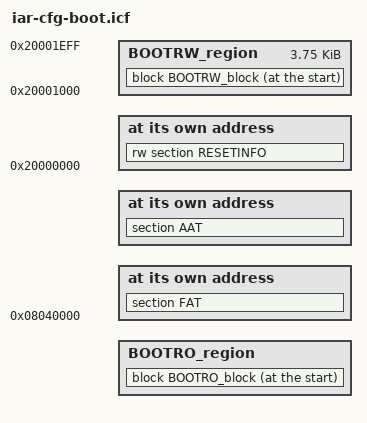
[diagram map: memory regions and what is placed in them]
// IAR V5 ILINK linker configuration file for bootloaders.
//
// Copyright 2009 by Ember Corporation. All rights reserved.                *80*

define memory mem with size = 4G;

// Lowest-common-denominator definitions that will work with all chip variations
//   RAM_TOP is artificially decreased to avoid interference with debug channels
define symbol RAM_BOTTOM          = 0x20000000;
define symbol RAM_TOP             = 0x20001EFF;

define symbol MFB_BOTTOM          = 0x08000000;
define symbol MFB_TOP             = 0x0801FFFF;

define symbol FIB_BOTTOM          = 0x08040000;
define symbol FIB_TOP             = 0x080407FF;

//=============================================================================
// Flash placement.

// Note: The bootloader does not support interrupts, so it does not include any
// interrupt vector table definitions other than what is included in the BAT.

// Define a region and block for containing the bootloader RO sections
// The Bootloader image lives at the bottom of the flash.  The BTL_SIZE 
// definition is passed in from the project definitions.
define symbol BOOTRO_BOTTOM          = MFB_BOTTOM;
define symbol BOOTRO_TOP             = MFB_BOTTOM + (BTL_SIZE-1);
define region BOOTRO_region          = mem:[from BOOTRO_BOTTOM to BOOTRO_TOP];
define block BOOTRO_block with fixed order { ro section BAT, 
                                             ro section .text, 
                                             ro section .rodata, 
                                             ro section .data_init };
"APP ro": place at start of BOOTRO_region { block BOOTRO_block };

// The FAT lives at a fixed address within the FIB
"FAT": place at address mem:FIB_BOTTOM { section FAT };

// The AAT will live immediately after the end of the bootloader
define symbol AAT_BOTTOM              = BOOTRO_TOP + 1;
"AAT": place at address mem:AAT_BOTTOM { section AAT };

//=============================================================================
// RAM placement.

// The call stack and reset info sections normally overlay on top of each other
//  at the bottom of ram, but since application bootloaders need space to load 
//  in a recovery image RAMEXE at the bottom of RAM, we only place the overlaid 
//  reset info section at the bottom of ram, and move the rest of the 
//  bootloaders ram usage up by 4K so that it doesn't get overwritten when
//  loading the RAMEXE.  The reset info area must live at the base of RAM as it
//  occupies this fixed location across all bootloader, application, and ramexe
//  images.
"RESETINFO": place at address mem:RAM_BOTTOM { rw section RESETINFO };

//Do not include the intializer tables or IAR init library code for any RW.
do not initialize { rw };
//But, .data and .textrw will be manually initialized so include init tables
// for them.
initialize manually { section .data, section .textrw };

// Define a region and block for containing the bootloader RW sections
//  Leave 4k free at the bottom of RAM to allow for recovery image
//  RAMEXE executable to be imported from eeprom by application bootloaders
define symbol BOOTRW_BOTTOM      = RAM_BOTTOM + 4K;
define symbol BOOTRW_TOP         = RAM_TOP;
define region BOOTRW_region      = mem:[from BOOTRW_BOTTOM to BOOTRW_TOP];
define block BOOTRW_block with fixed order { rw section CSTACK,
                                             rw section .data,
                                             rw section .bss };
"BOOT rw": place at start of BOOTRW_region { block BOOTRW_block };

